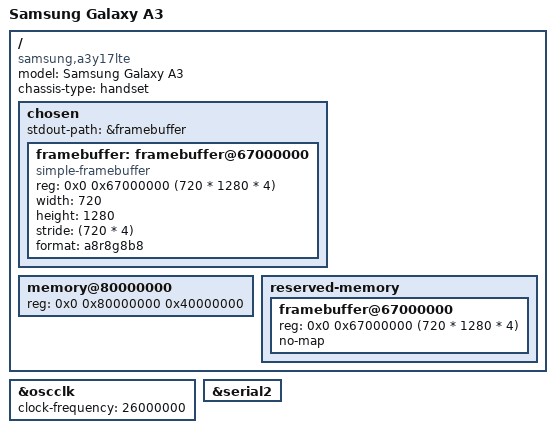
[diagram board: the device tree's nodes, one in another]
// SPDX-License-Identifier: GPL-2.0
/*
 * Samsung Galaxy A3 (a3y17lte) device tree source
 *
 * Copyright (c) 2018 Samsung Electronics Co., Ltd.
 * Copyright (c) 2025 Kaustabh Chakraborty <kauschluss@disroot.org>
 * Copyright (c) 2025 Jonas Heinrich <onny@project-insanity.org>
 */

/dts-v1/;
#include "exynos7870.dtsi"
#include <dt-bindings/gpio/gpio.h>
#include <dt-bindings/input/input.h>
#include <dt-bindings/interrupt-controller/irq.h>

/ {
	model = "Samsung Galaxy A3";
	compatible = "samsung,a3y17lte", "samsung,exynos7870";
	chassis-type = "handset";

	chosen {
		#address-cells = <2>;
		#size-cells = <1>;
		ranges;

		stdout-path = &framebuffer;

		framebuffer:framebuffer@67000000 {
			compatible = "simple-framebuffer";
			reg = <0x0 0x67000000 (720 * 1280 * 4)>;
			width = <720>;
			height = <1280>;
			stride = <(720 * 4)>;
			format = "a8r8g8b8";
		};
	};

	memory@80000000 {
		device_type = "memory";
		reg = <0x0 0x80000000 0x40000000>;
	};

	reserved-memory {
		#address-cells = <2>;
		#size-cells = <1>;
		ranges;

		framebuffer@67000000 {
			reg = <0x0 0x67000000 (720 * 1280 * 4)>;
			no-map;
		};
	};

};

&oscclk {
	clock-frequency = <26000000>;
};

&serial2 {
	status = "okay";
};
